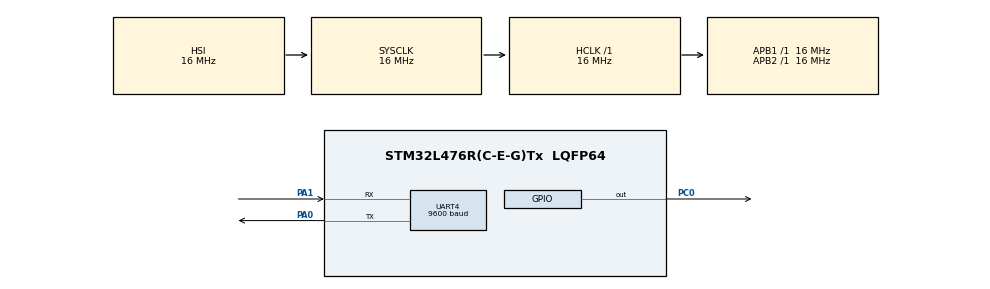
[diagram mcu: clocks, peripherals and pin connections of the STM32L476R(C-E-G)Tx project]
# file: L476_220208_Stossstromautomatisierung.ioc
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Mcu.Family=STM32L4
RCC.MSI_VALUE=4000000
PA14\ (JTCK-SWCLK).Mode=Serial_Wire
RCC.CortexFreq_Value=16000000
PH0-OSC_IN\ (PH0).Signal=RCC_OSC_IN
PC0.Signal=GPIO_Output
PH1-OSC_OUT\ (PH1).Signal=RCC_OSC_OUT
RCC.SYSCLKSource=RCC_SYSCLKSOURCE_HSI
ProjectManager.StackSize=0x400
PA14\ (JTCK-SWCLK).Signal=SYS_JTCK-SWCLK
ProjectManager.TargetToolchain=STM32CubeIDE
UART4.BaudRate=9600
RCC.HCLKFreq_Value=16000000
RCC.APB2TimFreq_Value=16000000
TIM3.Period=2000
UART4.Parity=PARITY_EVEN
RCC.USBFreq_Value=16000000
RCC.LSE_VALUE=32768
PA1.Signal=UART4_RX
RCC.AHBFreq_Value=16000000
PH1-OSC_OUT\ (PH1).Mode=HSE-External-Oscillator
RCC.HSE_VALUE=8000000
board=custom
RCC.VCOOutputFreq_Value=32000000
NVIC.TIM3_IRQn=true\:0\:0\:false\:false\:true\:true\:true
RCC.APB2Freq_Value=16000000
PA1.Mode=Asynchronous
VP_TIM2_VS_ClockSourceINT.Mode=Internal
TIM3.Prescaler=1000
NVIC.TIM2_IRQn=true\:0\:0\:false\:false\:true\:true\:true
RCC.ADCFreq_Value=16000000
PA0.Mode=Asynchronous
TIM2.Period=16000
Mcu.Name=STM32L476R(C-E-G)Tx
PA0.Signal=UART4_TX
PA13\ (JTMS-SWDIO).Mode=Serial_Wire
RCC.SYSCLKFreq_VALUE=16000000
Mcu.Package=LQFP64
TIM2.Prescaler=1000
RCC.HSI14CalibrationValue=16
ProjectManager.HeapSize=0x200
RCC.HSI_VALUE=16000000
NVIC.PriorityGroup=NVIC_PRIORITYGROUP_4
TIM2.TIM_MasterOutputTrigger=TIM_TRGO_UPDATE
RCC.APB1TimFreq_Value=16000000
TIM2.AutoReloadPreload=TIM_AUTORELOAD_PRELOAD_ENABLE
TIM3.TIM_MasterOutputTrigger=TIM_TRGO_UPDATE
PA13\ (JTMS-SWDIO).Signal=SYS_JTMS-SWDIO
PC0.GPIO_PuPd=GPIO_NOPULL
RCC.APB1Freq_Value=16000000
PH0-OSC_IN\ (PH0).Mode=HSE-External-Oscillator
VP_TIM3_VS_ClockSourceINT.Mode=Internal

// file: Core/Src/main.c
/* USER CODE BEGIN Header */
/**
  ******************************************************************************
  * @file           : main.c
  * @brief          : Main program body
  ******************************************************************************
  * @attention
  *
  * <h2><center>&copy; Copyright (c) 2022 STMicroelectronics.
  * All rights reserved.</center></h2>
  *
  * This software component is licensed by ST under BSD 3-Clause license,
  * the "License"; You may not use this file except in compliance with the
  * License. You may obtain a copy of the License at:
  *                        opensource.org/licenses/BSD-3-Clause
  *
  ******************************************************************************
  */
/* USER CODE END Header */
#include "main.h"

/* USER CODE BEGIN Includes */
#include "config.h"

/* USER CODE END Includes */

TIM_HandleTypeDef htim2;
TIM_HandleTypeDef htim3;

UART_HandleTypeDef huart4;

void SystemClock_Config(void);
static void MX_GPIO_Init(void);
static void MX_UART4_Init(void);
static void MX_TIM2_Init(void);
static void MX_TIM3_Init(void);

int main(void)
{

  /* MCU Configuration--------------------------------------------------------*/

  /* Reset of all peripherals, Initializes the Flash interface and the Systick. */
  HAL_Init();

  /* Configure the system clock */
  SystemClock_Config();

  /* Initialize all configured peripherals */
  MX_GPIO_Init();
  MX_UART4_Init();
  MX_TIM2_Init();
  MX_TIM3_Init();
  /* USER CODE BEGIN 2 */
  HAL_TIM_Base_Start_IT(&htim2);
  HAL_GPIO_WritePin(GPIOC, GPIO_PIN_0, GPIO_PIN_SET);

  /* USER CODE END 2 */

  /* Infinite loop */
  while (1)
  {

  }
}

void SystemClock_Config(void)
{
  RCC_OscInitTypeDef RCC_OscInitStruct = {0};
  RCC_ClkInitTypeDef RCC_ClkInitStruct = {0};
  RCC_PeriphCLKInitTypeDef PeriphClkInit = {0};

  /** Initializes the RCC Oscillators according to the specified parameters
  * in the RCC_OscInitTypeDef structure.
  */
  RCC_OscInitStruct.OscillatorType = RCC_OSCILLATORTYPE_HSI;
  RCC_OscInitStruct.HSIState = RCC_HSI_ON;
  RCC_OscInitStruct.HSICalibrationValue = RCC_HSICALIBRATION_DEFAULT;
  RCC_OscInitStruct.PLL.PLLState = RCC_PLL_NONE;
  if (HAL_RCC_OscConfig(&RCC_OscInitStruct) != HAL_OK)
  {
    Error_Handler();
  }
  /** Initializes the CPU, AHB and APB buses clocks
  */
  RCC_ClkInitStruct.ClockType = RCC_CLOCKTYPE_HCLK|RCC_CLOCKTYPE_SYSCLK
                              |RCC_CLOCKTYPE_PCLK1|RCC_CLOCKTYPE_PCLK2;
  RCC_ClkInitStruct.SYSCLKSource = RCC_SYSCLKSOURCE_HSI;
  RCC_ClkInitStruct.AHBCLKDivider = RCC_SYSCLK_DIV1;
  RCC_ClkInitStruct.APB1CLKDivider = RCC_HCLK_DIV1;
  RCC_ClkInitStruct.APB2CLKDivider = RCC_HCLK_DIV1;

  if (HAL_RCC_ClockConfig(&RCC_ClkInitStruct, FLASH_LATENCY_0) != HAL_OK)
  {
    Error_Handler();
  }
  PeriphClkInit.PeriphClockSelection = RCC_PERIPHCLK_UART4;
  PeriphClkInit.Uart4ClockSelection = RCC_UART4CLKSOURCE_PCLK1;
  if (HAL_RCCEx_PeriphCLKConfig(&PeriphClkInit) != HAL_OK)
  {
    Error_Handler();
  }
  /** Configure the main internal regulator output voltage
  */
  if (HAL_PWREx_ControlVoltageScaling(PWR_REGULATOR_VOLTAGE_SCALE1) != HAL_OK)
  {
    Error_Handler();
  }
}

static void MX_TIM2_Init(void)
{

  TIM_ClockConfigTypeDef sClockSourceConfig = {0};
  TIM_MasterConfigTypeDef sMasterConfig = {0};

  htim2.Instance = TIM2;
  htim2.Init.Prescaler = 1000;
  htim2.Init.CounterMode = TIM_COUNTERMODE_UP;
  htim2.Init.Period = 16000;
  htim2.Init.ClockDivision = TIM_CLOCKDIVISION_DIV1;
  htim2.Init.AutoReloadPreload = TIM_AUTORELOAD_PRELOAD_ENABLE;
  if (HAL_TIM_Base_Init(&htim2) != HAL_OK)
  {
    Error_Handler();
  }
  sClockSourceConfig.ClockSource = TIM_CLOCKSOURCE_INTERNAL;
  if (HAL_TIM_ConfigClockSource(&htim2, &sClockSourceConfig) != HAL_OK)
  {
    Error_Handler();
  }
  sMasterConfig.MasterOutputTrigger = TIM_TRGO_UPDATE;
  sMasterConfig.MasterSlaveMode = TIM_MASTERSLAVEMODE_DISABLE;
  if (HAL_TIMEx_MasterConfigSynchronization(&htim2, &sMasterConfig) != HAL_OK)
  {
    Error_Handler();
  }

}

static void MX_TIM3_Init(void)
{

  TIM_ClockConfigTypeDef sClockSourceConfig = {0};
  TIM_MasterConfigTypeDef sMasterConfig = {0};

  htim3.Instance = TIM3;
  htim3.Init.Prescaler = 1000;
  htim3.Init.CounterMode = TIM_COUNTERMODE_UP;
  htim3.Init.Period = 2000;
  htim3.Init.ClockDivision = TIM_CLOCKDIVISION_DIV1;
  htim3.Init.AutoReloadPreload = TIM_AUTORELOAD_PRELOAD_DISABLE;
  if (HAL_TIM_Base_Init(&htim3) != HAL_OK)
  {
    Error_Handler();
  }
  sClockSourceConfig.ClockSource = TIM_CLOCKSOURCE_INTERNAL;
  if (HAL_TIM_ConfigClockSource(&htim3, &sClockSourceConfig) != HAL_OK)
  {
    Error_Handler();
  }
  sMasterConfig.MasterOutputTrigger = TIM_TRGO_UPDATE;
  sMasterConfig.MasterSlaveMode = TIM_MASTERSLAVEMODE_DISABLE;
  if (HAL_TIMEx_MasterConfigSynchronization(&htim3, &sMasterConfig) != HAL_OK)
  {
    Error_Handler();
  }

}

static void MX_UART4_Init(void)
{

  huart4.Instance = UART4;
  huart4.Init.BaudRate = 9600;
  huart4.Init.WordLength = UART_WORDLENGTH_8B;
  huart4.Init.StopBits = UART_STOPBITS_1;
  huart4.Init.Parity = UART_PARITY_EVEN;
  huart4.Init.Mode = UART_MODE_TX_RX;
  huart4.Init.HwFlowCtl = UART_HWCONTROL_NONE;
  huart4.Init.OverSampling = UART_OVERSAMPLING_16;
  huart4.Init.OneBitSampling = UART_ONE_BIT_SAMPLE_DISABLE;
  huart4.AdvancedInit.AdvFeatureInit = UART_ADVFEATURE_NO_INIT;
  if (HAL_UART_Init(&huart4) != HAL_OK)
  {
    Error_Handler();
  }

}

static void MX_GPIO_Init(void)
{
  GPIO_InitTypeDef GPIO_InitStruct = {0};

  /* GPIO Ports Clock Enable */
  __HAL_RCC_GPIOH_CLK_ENABLE();
  __HAL_RCC_GPIOC_CLK_ENABLE();
  __HAL_RCC_GPIOA_CLK_ENABLE();

  /*Configure GPIO pin Output Level */
  HAL_GPIO_WritePin(GPIOC, GPIO_PIN_0, GPIO_PIN_RESET);

  /*Configure GPIO pin : PC0 */
  GPIO_InitStruct.Pin = GPIO_PIN_0;
  GPIO_InitStruct.Mode = GPIO_MODE_OUTPUT_PP;
  GPIO_InitStruct.Pull = GPIO_NOPULL;
  GPIO_InitStruct.Speed = GPIO_SPEED_FREQ_LOW;
  HAL_GPIO_Init(GPIOC, &GPIO_InitStruct);

}

void Error_Handler(void)
{
  __disable_irq();
  while (1)
  {
  }
}

/************************ (C) COPYRIGHT STMicroelectronics *****END OF FILE****/
